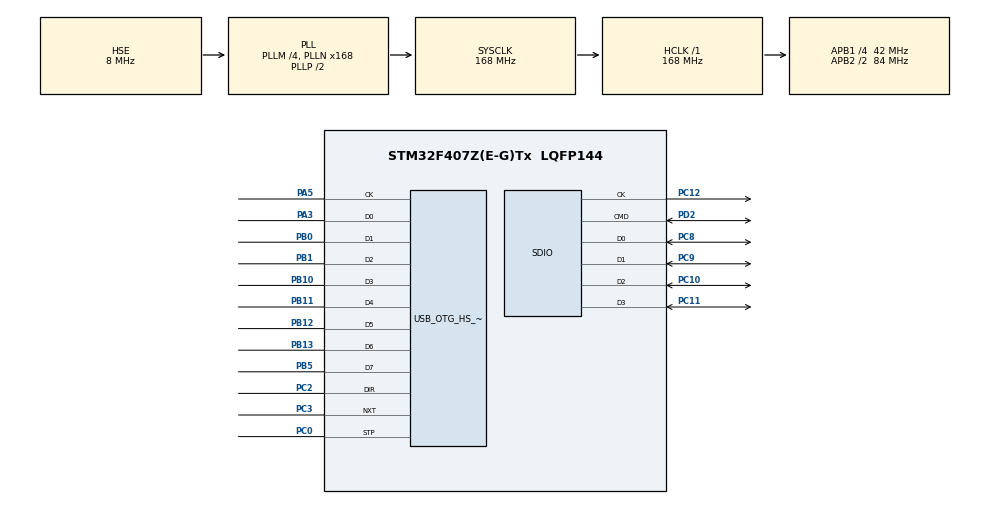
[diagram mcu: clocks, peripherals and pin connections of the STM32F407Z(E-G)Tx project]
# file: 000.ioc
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FATFS._CODE_PAGE=936
FATFS._FS_RPATH=2
FATFS._LFN_UNICODE=1
FATFS._USE_FIND=1
FATFS._USE_LFN=2
Mcu.Family=STM32F4
Mcu.Name=STM32F407Z(E-G)Tx
Mcu.Package=LQFP144
NVIC.OTG_HS_IRQn=true\:0\:0\:false\:false\:true\:false\:true\:true
NVIC.PriorityGroup=NVIC_PRIORITYGROUP_4
PA13.Mode=Serial_Wire
PA13.Signal=SYS_JTMS-SWDIO
PA14.Mode=Serial_Wire
PA14.Signal=SYS_JTCK-SWCLK
PA3.Mode=Host_HS
PA3.Signal=USB_OTG_HS_ULPI_D0
PA5.Mode=Host_HS
PA5.Signal=USB_OTG_HS_ULPI_CK
PB0.Mode=Host_HS
PB0.Signal=USB_OTG_HS_ULPI_D1
PB1.Mode=Host_HS
PB1.Signal=USB_OTG_HS_ULPI_D2
PB10.Mode=Host_HS
PB10.Signal=USB_OTG_HS_ULPI_D3
PB11.Mode=Host_HS
PB11.Signal=USB_OTG_HS_ULPI_D4
PB12.Mode=Host_HS
PB12.Signal=USB_OTG_HS_ULPI_D5
PB13.Mode=Host_HS
PB13.Signal=USB_OTG_HS_ULPI_D6
PB5.Mode=Host_HS
PB5.Signal=USB_OTG_HS_ULPI_D7
PC0.Mode=Host_HS
PC0.Signal=USB_OTG_HS_ULPI_STP
PC10.Mode=SD_4_bits_Wide_bus
PC10.Signal=SDIO_D2
PC11.Mode=SD_4_bits_Wide_bus
PC11.Signal=SDIO_D3
PC12.Mode=SD_4_bits_Wide_bus
PC12.Signal=SDIO_CK
PC2.Mode=Host_HS
PC2.Signal=USB_OTG_HS_ULPI_DIR
PC3.Mode=Host_HS
PC3.Signal=USB_OTG_HS_ULPI_NXT
PC8.Mode=SD_4_bits_Wide_bus
PC8.Signal=SDIO_D0
PC9.Mode=SD_4_bits_Wide_bus
PC9.Signal=SDIO_D1
PD2.Mode=SD_4_bits_Wide_bus
PD2.Signal=SDIO_CMD
PH0-OSC_IN.Mode=HSE-External-Oscillator
PH0-OSC_IN.Signal=RCC_OSC_IN
PH1-OSC_OUT.Mode=HSE-External-Oscillator
PH1-OSC_OUT.Signal=RCC_OSC_OUT
ProjectManager.HeapSize=0x2000
ProjectManager.StackSize=0x4000
ProjectManager.TargetToolchain=MDK-ARM V5.32
RCC.48MHZClocksFreq_Value=48000000
RCC.AHBFreq_Value=168000000
RCC.APB1CLKDivider=RCC_HCLK_DIV4
RCC.APB1Freq_Value=42000000
RCC.APB1TimFreq_Value=84000000
RCC.APB2CLKDivider=RCC_HCLK_DIV2
RCC.APB2Freq_Value=84000000
RCC.APB2TimFreq_Value=168000000
RCC.CortexFreq_Value=168000000
RCC.HCLKFreq_Value=168000000
RCC.HSE_VALUE=8000000
RCC.HSI_VALUE=16000000
RCC.LSE_VALUE=32768
RCC.PLLM=4
RCC.PLLN=168
RCC.PLLQ=7
RCC.PLLSourceVirtual=RCC_PLLSOURCE_HSE
RCC.SYSCLKFreq_VALUE=168000000
RCC.SYSCLKSource=RCC_SYSCLKSOURCE_PLLCLK
RCC.VCOOutputFreq_Value=336000000
USB_HOST.USBH_HandleTypeDef-MSC_HS=hUsbHostHS
USB_HOST.VirtualModeHS=Msc
USB_OTG_HS.VirtualMode-Host_HS=Host_HS
VP_FATFS_VS_SDIO.Mode=SDIO
VP_FATFS_VS_USB.Mode=USB
VP_USB_HOST_VS_USB_HOST_MSC_HS.Mode=MSC_HS
board=custom

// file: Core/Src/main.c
/* USER CODE BEGIN Header */
/**
  ******************************************************************************
  * @file           : main.c
  * @brief          : Main program body
  ******************************************************************************
  * @attention
  *
  * Copyright (c) 2023 STMicroelectronics.
  * All rights reserved.
  *
  * This software is licensed under terms that can be found in the LICENSE file
  * in the root directory of this software component.
  * If no LICENSE file comes with this software, it is provided AS-IS.
  *
  ******************************************************************************
  */
/* USER CODE END Header */
#include "main.h"
#include "fatfs.h"
#include "usb_host.h"

SD_HandleTypeDef hsd;

void SystemClock_Config(void);
static void MX_GPIO_Init(void);
static void MX_SDIO_SD_Init(void);
void MX_USB_HOST_Process(void);

/* USER CODE BEGIN 0 */
FATFS TF_Space;
FATFS UDISK_Space;

FRESULT res;

/*******************************************************************************
//Function Name  : FAT_Mount_TFCard(void)
//Description    :
//USE            : internal call
//Input          : None.
//Output         : None.
//Return         : None.
//EDITER         : ZBH
*******************************************************************************/
void FAT_Mount_TFCard(void)
{

res = f_mount(&TF_Space,(const TCHAR*)"1:",1);
	if(res == FR_OK)
	{

//		printf("FAT DEBUG:TF Card mount ok\r\n");

	}
	else
	{

//		printf("FAT DEBUG:TFcard mount err\r\n");

	}
}
/* USER CODE END 0 */

int main(void)
{
  /* USER CODE BEGIN 1 */
uint32_t i=0;
  /* USER CODE END 1 */

  /* MCU Configuration--------------------------------------------------------*/

  /* Reset of all peripherals, Initializes the Flash interface and the Systick. */
  HAL_Init();

  /* Configure the system clock */
  SystemClock_Config();

  /* Initialize all configured peripherals */
  MX_GPIO_Init();
  MX_SDIO_SD_Init();
  MX_FATFS_Init();
  MX_USB_HOST_Init();
  /* USER CODE BEGIN 2 */
	HAL_Delay(800);

  /* USER CODE END 2 */

  /* Infinite loop */
  /* USER CODE BEGIN WHILE */
  while (1)
  {
		i++;
		if(i==10000)
		{
		FAT_Mount_TFCard();
		}
    /* USER CODE END WHILE */
    MX_USB_HOST_Process();

  }
}

void SystemClock_Config(void)
{
  RCC_OscInitTypeDef RCC_OscInitStruct = {0};
  RCC_ClkInitTypeDef RCC_ClkInitStruct = {0};

  /** Configure the main internal regulator output voltage
  */
  __HAL_RCC_PWR_CLK_ENABLE();
  __HAL_PWR_VOLTAGESCALING_CONFIG(PWR_REGULATOR_VOLTAGE_SCALE1);

  /** Initializes the RCC Oscillators according to the specified parameters
  * in the RCC_OscInitTypeDef structure.
  */
  RCC_OscInitStruct.OscillatorType = RCC_OSCILLATORTYPE_HSE;
  RCC_OscInitStruct.HSEState = RCC_HSE_ON;
  RCC_OscInitStruct.PLL.PLLState = RCC_PLL_ON;
  RCC_OscInitStruct.PLL.PLLSource = RCC_PLLSOURCE_HSE;
  RCC_OscInitStruct.PLL.PLLM = 4;
  RCC_OscInitStruct.PLL.PLLN = 168;
  RCC_OscInitStruct.PLL.PLLP = RCC_PLLP_DIV2;
  RCC_OscInitStruct.PLL.PLLQ = 7;
  if (HAL_RCC_OscConfig(&RCC_OscInitStruct) != HAL_OK)
  {
    Error_Handler();
  }

  /** Initializes the CPU, AHB and APB buses clocks
  */
  RCC_ClkInitStruct.ClockType = RCC_CLOCKTYPE_HCLK|RCC_CLOCKTYPE_SYSCLK
                              |RCC_CLOCKTYPE_PCLK1|RCC_CLOCKTYPE_PCLK2;
  RCC_ClkInitStruct.SYSCLKSource = RCC_SYSCLKSOURCE_PLLCLK;
  RCC_ClkInitStruct.AHBCLKDivider = RCC_SYSCLK_DIV1;
  RCC_ClkInitStruct.APB1CLKDivider = RCC_HCLK_DIV4;
  RCC_ClkInitStruct.APB2CLKDivider = RCC_HCLK_DIV2;

  if (HAL_RCC_ClockConfig(&RCC_ClkInitStruct, FLASH_LATENCY_5) != HAL_OK)
  {
    Error_Handler();
  }
}

static void MX_SDIO_SD_Init(void)
{

  hsd.Instance = SDIO;
  hsd.Init.ClockEdge = SDIO_CLOCK_EDGE_RISING;
  hsd.Init.ClockBypass = SDIO_CLOCK_BYPASS_DISABLE;
  hsd.Init.ClockPowerSave = SDIO_CLOCK_POWER_SAVE_DISABLE;
  hsd.Init.BusWide = SDIO_BUS_WIDE_4B;
  hsd.Init.HardwareFlowControl = SDIO_HARDWARE_FLOW_CONTROL_DISABLE;
  hsd.Init.ClockDiv = 0;

}

static void MX_GPIO_Init(void)
{

  /* GPIO Ports Clock Enable */
  __HAL_RCC_GPIOH_CLK_ENABLE();
  __HAL_RCC_GPIOC_CLK_ENABLE();
  __HAL_RCC_GPIOA_CLK_ENABLE();
  __HAL_RCC_GPIOB_CLK_ENABLE();
  __HAL_RCC_GPIOD_CLK_ENABLE();

}

void Error_Handler(void)
{
  __disable_irq();
  while (1)
  {
  }
}
